# EFR32BG21A020F768IM32 register map
Vendor: Silicon Labs; Series: EFR32; File version: D
Registers are 32-bit, read-write, reset 0x0 unless marked. A register's access mark holds for its fields unless they carry their own. Offsets are from the block's base; [hi:lo] are bit positions; {n}, {i} and the like mark numbered series; 'fields as' and 'values as' point back to an identical list.

## SEMAILBOX_NS_HOST — SEMAILBOX_NS_HOST Registers
Base 0x5C000000
Same registers: SEMAILBOX_S_HOST 0x4C000000
{0x0+4i} DATA{i} (i=0..15) — RX/TX FIFO DATA
  [31:0] DATA — FIFO Data
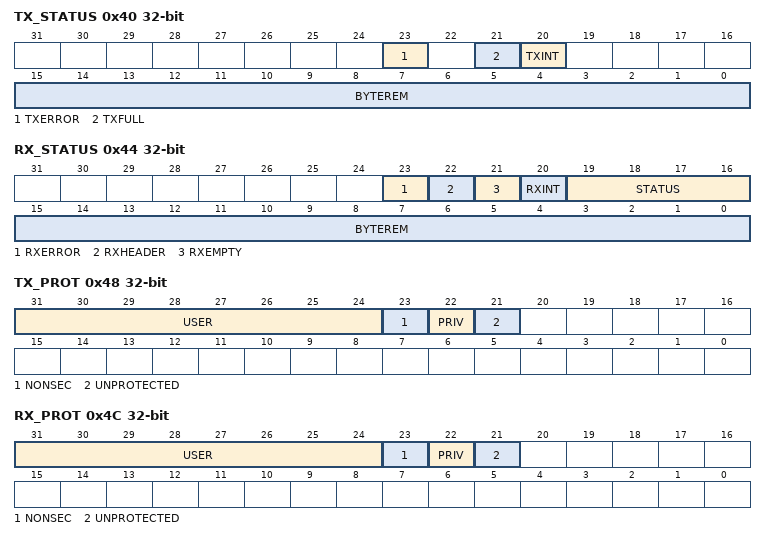
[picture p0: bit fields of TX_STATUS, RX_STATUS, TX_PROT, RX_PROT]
0x40 TX_STATUS ro
  [23] TXERROR — TX Error Flag
  [21] TXFULL — TX FIFO Full
  [20] TXINT — Interrupt Status
  [15:0] BYTEREM — Bytes Remaining
0x44 RX_STATUS ro
  [23] RXERROR — RX Error Flag
  [22] RXHEADER
  [21] RXEMPTY — RX FIFO Empty
  [20] RXINT — Interrupt Status
  [19:16] STATUS — Message Status
  [15:0] BYTEREM — Bytes Remaining
0x48 TX_PROT ro
  [31:24] USER — User Bits
  [23] NONSEC — Non-Secure Access
  [22] PRIV — Privileged Access
  [21] UNPROTECTED
0x4C RX_PROT ro
  fields as TX_PROT
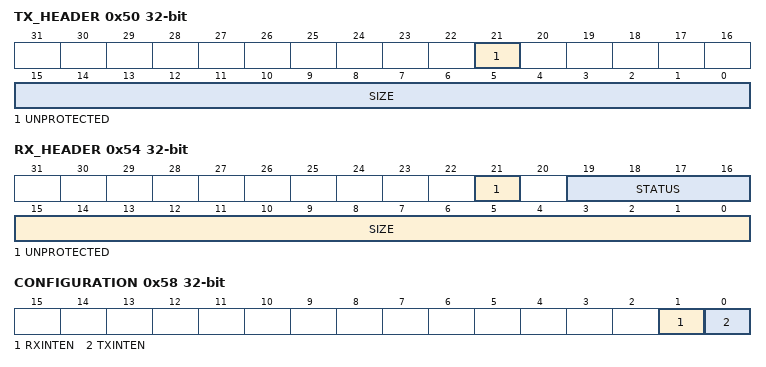
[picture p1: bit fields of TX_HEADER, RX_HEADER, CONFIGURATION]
0x50 TX_HEADER wo
  [21] UNPROTECTED
  [15:0] SIZE — Command Size
0x54 RX_HEADER ro
  [21] UNPROTECTED
  [19:16] STATUS — Command Status
  [15:0] SIZE
0x58 CONFIGURATION
  [1] RXINTEN — RX Interrupt Enable
  [0] TXINTEN — TX Interrupt Enable

## SYSCFG_NS — SYSCFG_NS Registers
Base 0x5007C000
Same registers: SYSCFG_S 0x4007C000
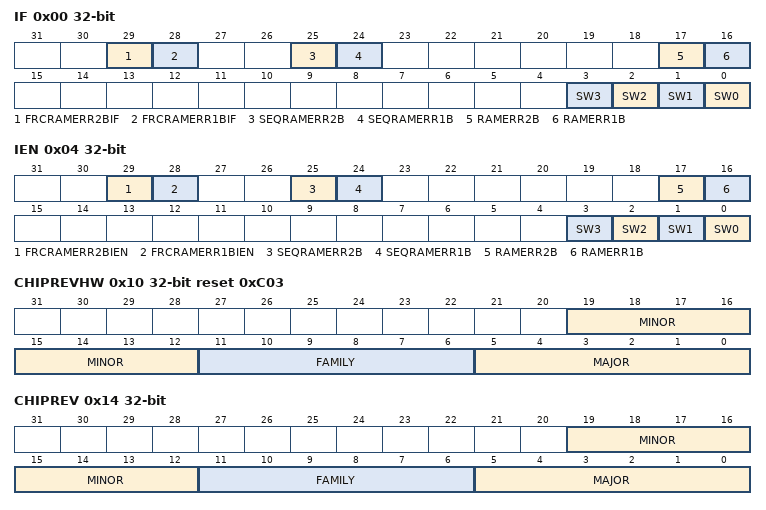
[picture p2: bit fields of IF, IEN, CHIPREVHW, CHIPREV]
0x00 IF
  [29] FRCRAMERR2BIF — FRCRAM 2-bit ECC Error Interrupt flag
  [28] FRCRAMERR1BIF — FRCRAM 1-bit ECC Error Interrupt flag
  [25] SEQRAMERR2B — SEQRAM 2-bit ECC Error Interrupt flag
  [24] SEQRAMERR1B — SEQRAM 1-bit ECC Error Interrupt flag
  [17] RAMERR2B — RAM 2-bit ECC Error Interrupt flag
  [16] RAMERR1B — RAM 1-bit ECC Error Interrupt flag
  [n] SW{n} (n=0..3) — Software Interrupt {n}
0x04 IEN
  [29] FRCRAMERR2BIEN — FRCRAM 2-bit ECC Error Interrupt enable
  [28] FRCRAMERR1BIEN — FRCRAM 1-bit ECC Error Interrupt enable
  [25] SEQRAMERR2B — SEQRAM 2-bit ECC Error Interrupt enable
  [24] SEQRAMERR1B — SEQRAM 1-bit ECC Error Interrupt enable
  [17] RAMERR2B — RAM 2-bit ECC Error Interrupt enable
  [16] RAMERR1B — RAM 1-bit ECC Error Interrupt enable
  [n] SW{n} (n=0..3) — Software Interrupt {n}
0x10 CHIPREVHW reset 0xC03
  [19:12] MINOR — Chip Rev Minor value
  [11:6] FAMILY — Chip Family value
  [5:0] MAJOR — Chip Rev Major value
0x14 CHIPREV
  [19:12] MINOR — Chip Rev Minor value
  [11:6] FAMILY — Chip Family value
    48=MG21 (Product is in MG21 family); 49=BG21 (Product is in BG21 family); 51=MR21 (Product is in MR21 family)
  [5:0] MAJOR — Chip Rev Major value
0x24 CFGSYSTIC
  [0] SYSTICEXTCLKEN — SysTick External Clock Enable
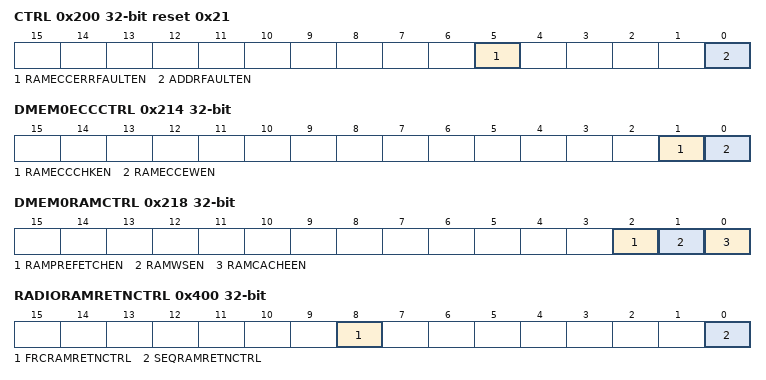
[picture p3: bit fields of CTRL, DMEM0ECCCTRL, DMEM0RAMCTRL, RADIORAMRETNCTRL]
0x200 CTRL reset 0x21
  [5] RAMECCERRFAULTEN — Two bit ECC Error Bus Fault Response Enable
  [0] ADDRFAULTEN — Invalid Address Bus Fault Response Enable
0x208 DMEM0RETNCTRL
  [4:0] RAMRETNCTRL — DMEM0 blockset retention control
    0=ALLON (None of the RAM blocks powered down); 16=BLK5 (Power down RAM block 5 (address range 0x20014000-0x20017FFF)); 24=BLK4TO5 (Power down RAM blocks 4 and above (address range 0x20010000-0x20017FFF)); 28=BLK3TO5 (Power down RAM blocks 3 and above (address range 0x2000C000-0x20017FFF)); 30=BLK2TO5 (Power down RAM blocks 2 and above (address range 0x20008000-0x20017FFF)); 31=BLK1TO5 (Power down RAM blocks 1 and above (address range 0x20004000-0x20017FFF))
0x210 DMEM0ECCADDR ro
  [31:0] DMEM0ECCADDR — DMEM0 RAM ECC Error Address
0x214 DMEM0ECCCTRL
  [1] RAMECCCHKEN — RAM ECC Check Enable
  [0] RAMECCEWEN — RAM ECC Write Enable
0x218 DMEM0RAMCTRL
  [2] RAMPREFETCHEN — RAM Prfetch Enable
  [1] RAMWSEN — RAM WAIT STATE Enable
  [0] RAMCACHEEN — RAM CACHE Enable
0x400 RADIORAMRETNCTRL
  [8] FRCRAMRETNCTRL — FRCRAM Memory Shutdown Control Register
    0=ALLON (FRCRAM not powered down); 1=FRCBLK (Power down FRCRAM (address range 0x50002000-0x50002FFF))
  [0] SEQRAMRETNCTRL — SEQRAM Memory Shutdown Control Register
    0=ALLON (SEQRAM not powered down); 1=SEQBLK (Power down SEQRAM (address range 0x50000000-0x50001FFF))
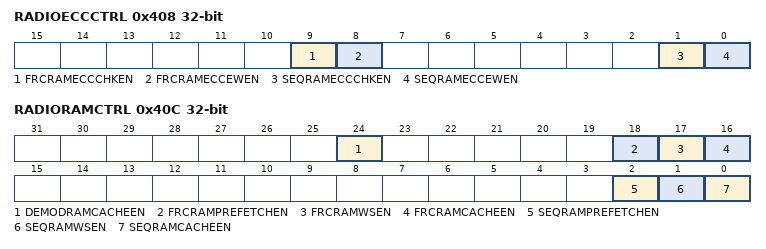
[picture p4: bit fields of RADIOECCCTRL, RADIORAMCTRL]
0x408 RADIOECCCTRL
  [9] FRCRAMECCCHKEN — FRCRAM ECC Check Enable
  [8] FRCRAMECCEWEN — FRCRAM ECC Write Enable
  [1] SEQRAMECCCHKEN — SEQRAM ECC Check Enable
  [0] SEQRAMECCEWEN — SEQRAM ECC Write Enable
0x40C RADIORAMCTRL
  [24] DEMODRAMCACHEEN — DEMODRAM CACHE Enable
  [18] FRCRAMPREFETCHEN — FRCRAM Prfetch Enable
  [17] FRCRAMWSEN — FRCRAM WAIT STATE Enable
  [16] FRCRAMCACHEEN — FRCRAM CACHE Enable
  [2] SEQRAMPREFETCHEN — SEQRAM Prfetch Enable
  [1] SEQRAMWSEN — SEQRAM WAIT STATE Enable
  [0] SEQRAMCACHEEN — SEQRAM CACHE Enable
0x410 SEQRAMECCADDR ro
  [31:0] SEQRAMECCADDR — SEQRAM ECC Error Address
0x414 FRCRAMECCADDR ro
  [31:0] FRCRAMECCADDR — FRCRAM ECC Error Address
